# 3065PNPIRE register map
File version: 1.0
Registers are 32-bit, access per field, reset 0x0 unless marked. A register's access mark holds for its fields unless they carry their own. Offsets are from the block's base; [hi:lo] are bit positions; {n}, {i} and the like mark numbered series.

## CRC — CRC peripheral interface
Base 0x14800000
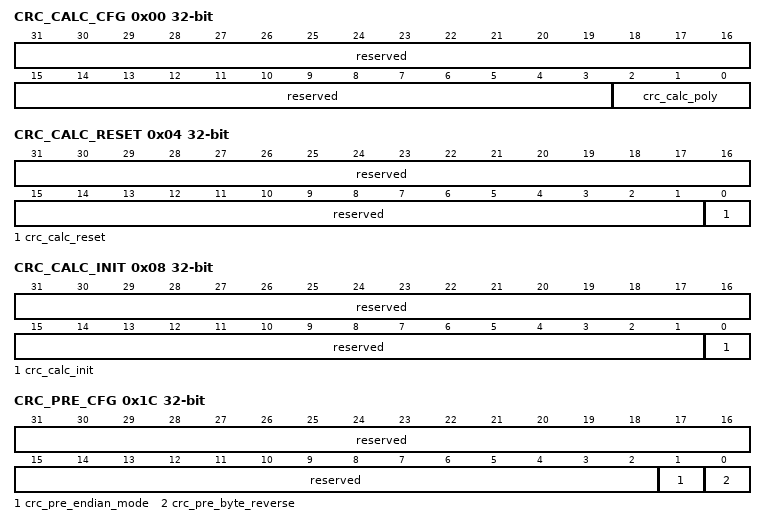
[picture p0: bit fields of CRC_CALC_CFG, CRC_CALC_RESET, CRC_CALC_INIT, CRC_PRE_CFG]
0x00 CRC_CALC_CFG — CRC_CALC_CFG为CRC计算模块，配置寄存器。
  [31:3] reserved ro — 保留。
  [2:0] crc_calc_poly rw — CRC计算模块，多项式配置： 000：CRC-8，多项式0x07；07； 001：保留； 010：CRC-16，多项式0x8005； 011：CRC-16，多项式0x1021； 100：CRC-32，多项式0x04c11d87； 其他：保留。
0x04 CRC_CALC_RESET — CRC_CALC_RESET为CRC计算模块软复位寄存器，复位计算，不复位配置。
  [31:1] reserved ro — 保留。
  [0] crc_calc_reset rw write-1-clears — CRC计算模块软复，该位域写1自动清零。复位CRC计算，不复位配置。
0x08 CRC_CALC_INIT — CRC_CALC_INIT为CRC计算模块，初始化寄存器。
  [31:1] reserved ro — 保留。
  [0] crc_calc_init rw write-1-clears — CRC初始值加载信号。 该位域写1自动清零，CRC计算初始化。 软件写入该位域，CRC计算初始化完成后，CRC从CRC初始值（CRC_CALC_INIT_VALUE[crc_calc_init_value]位域）开始计算。 注意：软件配置该位域后，再写入CRC_DATA_IN[crc_data_in]位域开始计算。
0x0C CRC_POST_XOR_VALUE rw — CRC_POST_XOR_VALUE为CRC后级处理，异或值寄存器。
  [31:0] crc_post_xor_value — crc后级处理，异或值（XOR）。
0x10 CRC_CALC_INIT_VALUE rw — CRC_CALC_INIT_VALUE为CRC计算模块，初始值寄存器。
  [31:0] crc_calc_init_value — CRC计算模块，初始值。
0x14 CRC_DATA_IN rw — CRC_DATA_IN为CRC输入数据寄存器。
  [31:0] crc_data_in — CRC输入数据。软件写入需要计算的数据。
0x18 CRC_OUT ro — CRC_OUT为CRC结果寄存器。
  [31:0] crc_out — CRC结果，超过CRC多项式宽度的比特位是0。
0x1C CRC_PRE_CFG — CRC_PRE_CFG为CRC前级处理，配置寄存器。
  [31:2] reserved ro — 保留。
  [1] crc_pre_endian_mode rw — crc_data_in数据大小端。 0：小端； 1：大端。
  [0] crc_pre_byte_reverse rw — crc_data_in数据在字节内，按位反序（RefIn）。 0：不反序； 1：反序。
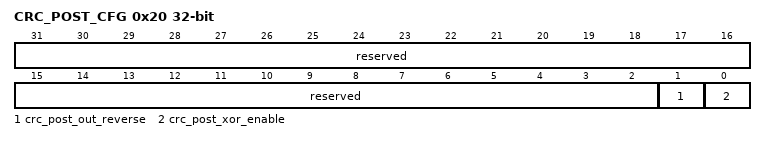
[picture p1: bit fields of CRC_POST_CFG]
0x20 CRC_POST_CFG — CRC_POST_CFG为CRC输出控制寄存器。
  [31:2] reserved ro — 保留。
  [1] crc_post_out_reverse rw — CRC结果在多项式宽度内，按位反序（RefOut）。 0：不反序； 1：反序。
  [0] crc_post_xor_enable rw — CRC结果异或（XOR)。 0：不异或； 1：异或。

## CAPM_COMM — CAPM_COMM peripheral interface
Base 0x14B03000
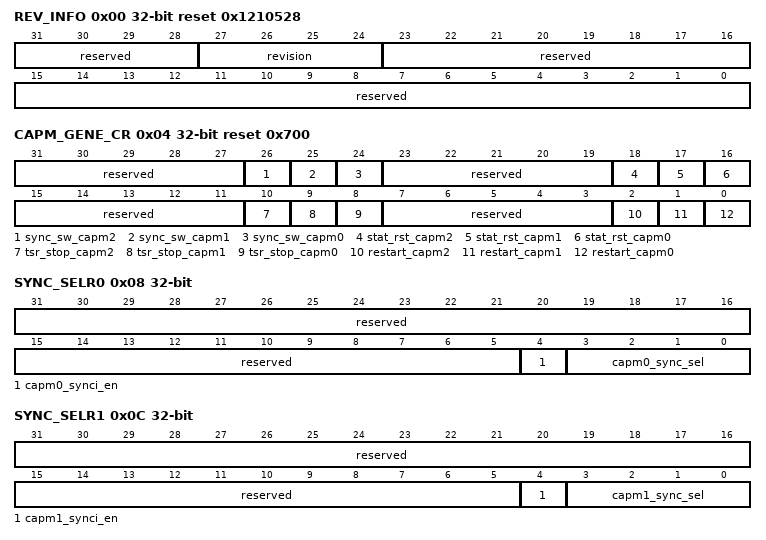
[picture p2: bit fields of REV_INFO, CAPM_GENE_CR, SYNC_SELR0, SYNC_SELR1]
0x00 REV_INFO ro reset 0x1210528 — REV_INFO为Revision Information，版本信息寄存器。
  [31:28] reserved — 保留。
  [27:24] revision — IP版本号。
  [23:0] reserved — 保留。
0x04 CAPM_GENE_CR reset 0x700 — CAPM_GENE_CR为Capture Module General Control Register，通用配置寄存器。
  [31:27] reserved ro — 保留。
  [26] sync_sw_capm2 rw write-1-clears — 触发CAPM2同步，TSR的值被同步为SYNC_PHS的值，同时重启捕获序列。软件写1后自动清零。 0：不同步； 1：同步。写1后自动清零。
  [25] sync_sw_capm1 rw write-1-clears — 触发CAPM1同步，TSR的值被同步为SYNC_PHS的值，同时重启捕获序列。软件写1后自动清零。 0：不同步； 1：同步。写1后自动清零。
  [24] sync_sw_capm0 rw write-1-clears — 触发CAPM0同步，TSR的值被同步为SYNC_PHS的值，同时重启捕获序列。软件写1后自动清零。 0：不同步； 1：同步。写1后自动清零。
  [23:19] reserved ro — 保留。
  [18] stat_rst_capm2 rw write-1-clears — CAPM2工作状态复位，复位范围包括：TSR计数器；EAR计数器；捕获序列；TSR分频计数器；原始中断。 0：不复位； 1：复位。写1后自动清零。
  [17] stat_rst_capm1 rw write-1-clears — CAPM1工作状态复位，复位范围包括：TSR计数器、EAR计数器、捕获序列、TSR分频计数器、原始中断。 0：不复位； 1：复位。写1后自动清零。
  [16] stat_rst_capm0 rw write-1-clears — CAPM0工作状态复位，复位范围包括：TSR计数器、EAR计数器、捕获序列、TSR分频计数器、原始中断。 0：不复位； 1：复位。写1后自动清零。
  [15:11] reserved ro — 保留。
  [10] tsr_stop_capm2 rw — CAPM2 TSR暂停计数使能。 0：CAPM2 TSR继续计数； 1：CAPM2 TSR暂停计数。
  [9] tsr_stop_capm1 rw — CAPM1 TSR暂停计数使能。 0：CAPM1 TSR继续计数； 1：CAPM1 TSR暂停计数。
  [8] tsr_stop_capm0 rw — CAPM0 TSR暂停计数使能。 0：CAPM0 TSR继续计数； 1：CAPM0 TSR暂停计数。
  [7:3] reserved ro — 保留。
  [2] restart_capm2 rw write-1-clears — CAPM2开始一次新的单轮次捕获。 0：不开始； 1：开始。写1后自动清零。
  [1] restart_capm1 rw write-1-clears — CAPM1开始一次新的单轮次捕获。 0：不开始； 1：开始。写1后自动清零。
  [0] restart_capm0 rw write-1-clears — CAPM0开始一次新的单轮次捕获。 0：不开始； 1：开始。写1后自动清零。
0x08 SYNC_SELR0 — SYNC_SELR0为Sync Selection Register(for CAPM0)，CAPM0同步设置选择寄存器。
  [31:5] reserved ro — 保留。
  [4] capm0_synci_en rw — CAPM0 硬件，软件同步使能。 0：不使能； 1：使能。
  [3:0] capm0_sync_sel rw — CAPM0的硬件同步源选择。 0x0：无同步源； 0x1：APT0同步输出信号APT0SYNCO； 0x2：APT1同步输出信号APT1SYNCO； 0x3：APT2同步输出信号APT2SYNCO； 0x4：APT3同步输出信号APT3SYNCO； 0x5：APT4同步输出信号APT4SYNCO； 0x6：APT5同步输出信号APT5SYNCO； 0x7：APT6同步输出信号APT6SYNCO； 0x8：APT7同步输出信号APT7SYNCO； 0x9：APT8同步输出信号APT8SYNCO； 其他：无同步源。
0x0C SYNC_SELR1 — SYNC_SELR1为Sync Selection Register(for CAPM1)，CAPM1同步设置选择寄存器。
  [31:5] reserved ro — 保留。
  [4] capm1_synci_en rw — CAPM1硬件，软件同步使能。 0：不使能； 1：使能。
  [3:0] capm1_sync_sel rw — CAPM1的硬件同步源选择： 同capm0_sync_sel。
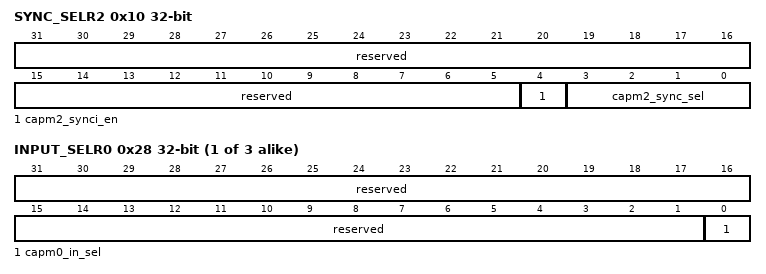
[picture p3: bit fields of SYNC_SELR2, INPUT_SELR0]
0x10 SYNC_SELR2 — SYNC_SELR2为Sync Selection Register(for CAPM2)，CAPM2同步设置选择寄存器。
  [31:5] reserved ro — 保留。
  [4] capm2_synci_en rw — CAPM2 硬件，软件同步使能。 0：不使能； 1：使能。
  [3:0] capm2_sync_sel rw — CAPM2的硬件同步源选择： 同capm0_sync_sel。
{0x28+4i} INPUT_SELR{i} (i=0..2) — INPUT_SELR{i}为Input Source Selection Register(for CAPM{i})，CAPM{i}输入源选择寄存器。
  [31:1] reserved ro — 保留。
  [0] capm{i}_in_sel rw — CAPM{i}输入源选择。 0：CAPM{i}_IN； 1：无。
